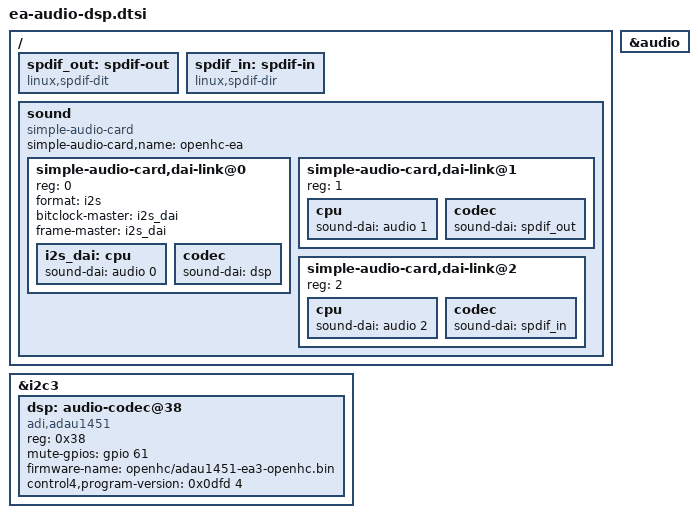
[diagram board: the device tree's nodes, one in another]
// SPDX-License-Identifier: GPL-2.0
/*
 * EA-3 audio (`audio-dsp`): CE5300 I2S -> ADAU1451 at i2c3 0x38 -> AK4621,
 * and the CE5300's S/PDIF out and in on the coax jacks.
 * The CE5300 is the I2S clock master; every DSP serial port is a slave.
 * See board/ea/common/firmware/dsp/adau1451/README.md.
 */
#include "ea-adau1451.dtsi"

#define EA_LINE_10	"audio_sense0"
#define EA_LINE_61	"dac_mute"

&audio {
	/* 0: I2S out (the DSP), 1: S/PDIF out (coax out), 2: S/PDIF in (coax in) */
	#sound-dai-cells = <1>;
};

&i2c3 {
	dsp: audio-codec@38 {
		compatible = "adi,adau1451";
		reg = <0x38>;
		#sound-dai-cells = <0>;
		mute-gpios = <&gpio 61 GPIO_ACTIVE_HIGH>;
		firmware-name = "openhc/adau1451-ea3-openhc.bin";
		control4,program-version = <0x0dfd 4>;
	};
};

/ {
	spdif_out: spdif-out {
		compatible = "linux,spdif-dit";
		#sound-dai-cells = <0>;
	};

	spdif_in: spdif-in {
		compatible = "linux,spdif-dir";
		#sound-dai-cells = <0>;
	};

	sound {
		compatible = "simple-audio-card";
		/* ALSA card id "openhcea"; PCM device n is dai-link n */
		simple-audio-card,name = "openhc-ea";
		#address-cells = <1>;
		#size-cells = <0>;

		simple-audio-card,dai-link@0 {
			reg = <0>;
			format = "i2s";
			bitclock-master = <&i2s_dai>;
			frame-master = <&i2s_dai>;

			i2s_dai: cpu {
				sound-dai = <&audio 0>;
			};
			codec {
				sound-dai = <&dsp>;
			};
		};

		simple-audio-card,dai-link@1 {
			reg = <1>;

			cpu {
				sound-dai = <&audio 1>;
			};
			codec {
				sound-dai = <&spdif_out>;
			};
		};

		simple-audio-card,dai-link@2 {
			reg = <2>;

			cpu {
				sound-dai = <&audio 2>;
			};
			codec {
				sound-dai = <&spdif_in>;
			};
		};
	};
};
